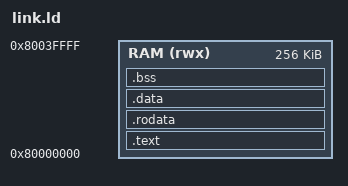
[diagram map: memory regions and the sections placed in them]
OUTPUT_ARCH("riscv")
ENTRY(_start)

MEMORY
{
    RAM (rwx) : ORIGIN = 0x80000000, LENGTH = 256K
}

SECTIONS
{
    .text : {
        . = ALIGN(4);
        __text_start = .;
        KEEP(*(.text.entry))
        *(.text .text.*)
        . = ALIGN(4);
        __text_end = .;
    } > RAM

    .rodata : {
        . = ALIGN(4);
        *(.rodata .rodata.*)
        *(.srodata .srodata.*)
    } > RAM

    .data : {
        . = ALIGN(4);
        __data_start = .;
        *(.data .data.*)
        *(.sdata .sdata.*)
        . = ALIGN(4);
        __data_end = .;
    } > RAM

    .bss : {
        . = ALIGN(4);
        __bss_start = .;
        *(.bss .bss.*)
        *(.sbss .sbss.*)
        *(COMMON)
        . = ALIGN(4);
        __bss_end = .;
    } > RAM

    . = ALIGN(16);
    _end = .;
    __stack_top = ORIGIN(RAM) + LENGTH(RAM);
}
